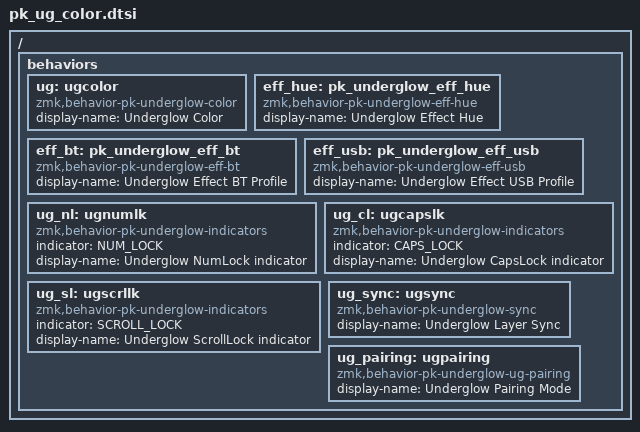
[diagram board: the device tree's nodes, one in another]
#include "../../include/dt-bindings/zmk/hid_indicators.h"

/ {
    behaviors {
        ug: ugcolor {
            compatible = "zmk,behavior-pk-underglow-color";
            #binding-cells = <1>;
            display-name = "Underglow Color";
        };

        eff_hue: pk_underglow_eff_hue {
            compatible = "zmk,behavior-pk-underglow-eff-hue";
            #binding-cells = <1>;
            display-name = "Underglow Effect Hue";
        };

        eff_bt: pk_underglow_eff_bt {
            compatible = "zmk,behavior-pk-underglow-eff-bt";
            #binding-cells = <1>;
            display-name = "Underglow Effect BT Profile";
        };

        eff_usb: pk_underglow_eff_usb {
            compatible = "zmk,behavior-pk-underglow-eff-usb";
            #binding-cells = <0>;
            display-name = "Underglow Effect USB Profile";
        };

        ug_nl: ugnumlk {
            compatible = "zmk,behavior-pk-underglow-indicators";
            indicator = <NUM_LOCK>;
            #binding-cells = <2>;
            display-name = "Underglow NumLock indicator";
        };

        ug_cl: ugcapslk {
            compatible = "zmk,behavior-pk-underglow-indicators";
            indicator = <CAPS_LOCK>;
            #binding-cells = <2>;
            display-name = "Underglow CapsLock indicator";
        };

        ug_sl: ugscrllk {
            compatible = "zmk,behavior-pk-underglow-indicators";
            indicator = <SCROLL_LOCK>;
            #binding-cells = <2>;
            display-name = "Underglow ScrollLock indicator";
        };


        ug_sync: ugsync {
            compatible = "zmk,behavior-pk-underglow-sync";
            #binding-cells = <0>;
            display-name = "Underglow Layer Sync";
        };

        ug_pairing: ugpairing {
            compatible = "zmk,behavior-pk-underglow-ug-pairing";
            #binding-cells = <2>;
            display-name = "Underglow Pairing Mode";
        };
    };
};
